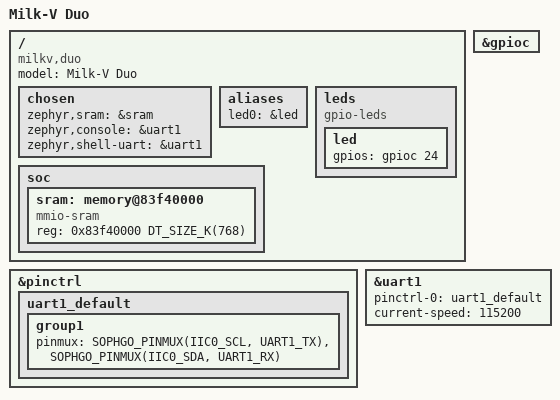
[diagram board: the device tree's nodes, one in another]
/*
 * Copyright (c) 2023-2024 Chen Xingyu <hi@xingrz.me>
 * SPDX-License-Identifier: Apache-2.0
 */

/dts-v1/;

#include <sophgo/cv180x.dtsi>
#include <zephyr/dt-bindings/gpio/gpio.h>

/ {
	model = "Milk-V Duo";
	compatible = "milkv,duo";

	chosen {
		zephyr,sram = &sram;
		zephyr,console = &uart1;
		zephyr,shell-uart = &uart1;
	};

	aliases {
		led0 = &led;
	};

	leds {
		compatible = "gpio-leds";

		led: led {
			gpios = <&gpioc 24 GPIO_ACTIVE_HIGH>;
		};
	};

	soc {
		sram: memory@83f40000 {
			compatible = "mmio-sram";
			reg = <0x83f40000 DT_SIZE_K(768)>;
		};
	};
};

&pinctrl {
	uart1_default: uart1_default {
		group1 {
			pinmux = <SOPHGO_PINMUX(IIC0_SCL, UART1_TX)>,
				 <SOPHGO_PINMUX(IIC0_SDA, UART1_RX)>;
		};
	};
};

&gpioc {
	status = "okay";
};

&uart1 {
	status = "okay";
	pinctrl-0 = <&uart1_default>;
	pinctrl-names = "default";
	current-speed = <115200>;
};
